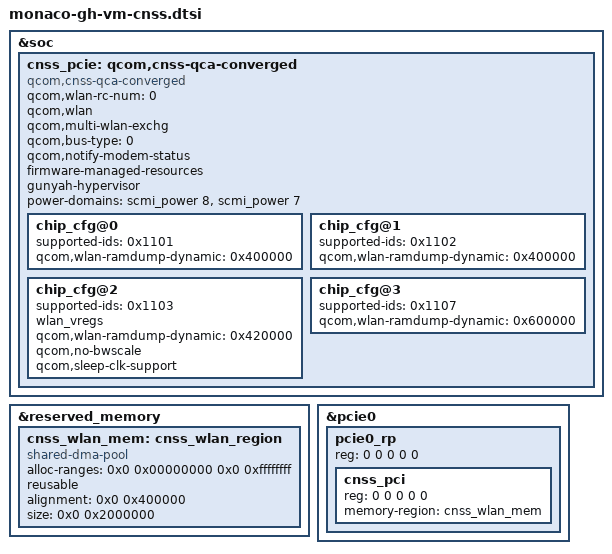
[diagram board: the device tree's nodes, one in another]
// SPDX-License-Identifier: BSD-3-Clause

/*
 * Copyright (c) Qualcomm Technologies, Inc. and/or its subsidiaries.
 */

&soc {
	cnss_pcie: qcom,cnss-qca-converged {
		compatible = "qcom,cnss-qca-converged";
		qcom,wlan-rc-num = <0>;
		qcom,wlan;
		qcom,multi-wlan-exchg;
		qcom,bus-type=<0>;
		qcom,notify-modem-status;
		firmware-managed-resources;
		gunyah-hypervisor;

		#address-cells=<1>;
		#size-cells=<1>;
		ranges = <0xb0000000 0xb0000000 0x10000>;

		/*
		 * WLAN and BT power supplies are controlled by PMIC GPIOs,
		 * not through the standard Linux regulator framework.
		 *
		 * Although WLAN and BT share the same physical regulator,
		 * they were previously assigned to separate SCMI power
		 * domains. Since GearVM does not provide a voting mechanism
		 * for PMIC GPIO operations, disabling BT could de-assert
		 * the PMIC GPIO and unintentionally remove power from WLAN,
		 * resulting in a PCIe link down.
		 *
		 * Assign WLAN and BT to the same regulator power domain
		 * (<&scmi_power 8>) so that the genpd framework can provide
		 * proper power voting from the kernel layer.
		 */
		power-domains = <&scmi_power 8>, <&scmi_power 7>;
		power-domain-names = "wlan_ldo", "wlan_gpio";

		chip_cfg@0 {
			supported-ids = <0x1101>;
			qcom,wlan-ramdump-dynamic = <0x400000>;
		};

		chip_cfg@1 {
			supported-ids = <0x1102>;
			qcom,wlan-ramdump-dynamic = <0x400000>;
		};

		chip_cfg@2 {
			supported-ids = <0x1103>;
			wlan_vregs;
			qcom,wlan-ramdump-dynamic = <0x420000>;
			qcom,no-bwscale;
			qcom,sleep-clk-support;
		};

		chip_cfg@3 {
			supported-ids = <0x1107>;
			qcom,wlan-ramdump-dynamic = <0x600000>;
		};
	};
};

&reserved_memory {
	cnss_wlan_mem: cnss_wlan_region {
		compatible = "shared-dma-pool";
		alloc-ranges = <0x0 0x00000000 0x0 0xffffffff>;
		reusable;
		alignment = <0x0 0x400000>;
		size = <0x0 0x2000000>;
	};
};

&pcie0 {
	pcie0_rp: pcie0_rp {
		reg = <0 0 0 0 0>;
		#address-cells = <5>;
		#size-cells = <0>;
		cnss_pci: cnss_pci {
			reg = <0 0 0 0 0>;
			memory-region = <&cnss_wlan_mem>;
		};
	};
};
